# KM1M7CF05 register map
Vendor: Nuvoton Technology Corporation Japan; Series: KM1M7CF; File version: 1.0.3
CPU: CM7 r1p2, little endian, MPU, FPU, double-precision FPU, I-cache, D-cache, ITCM, DTCM, 4 interrupt priority bits
Registers are 16-bit, access per field, no defined reset value unless marked. A register's access mark holds for its fields unless they carry their own. Offsets are from the block's base; [hi:lo] are bit positions; {n}, {i} and the like mark numbered series.

## FL — Flash Memory
Base 0x4001C000
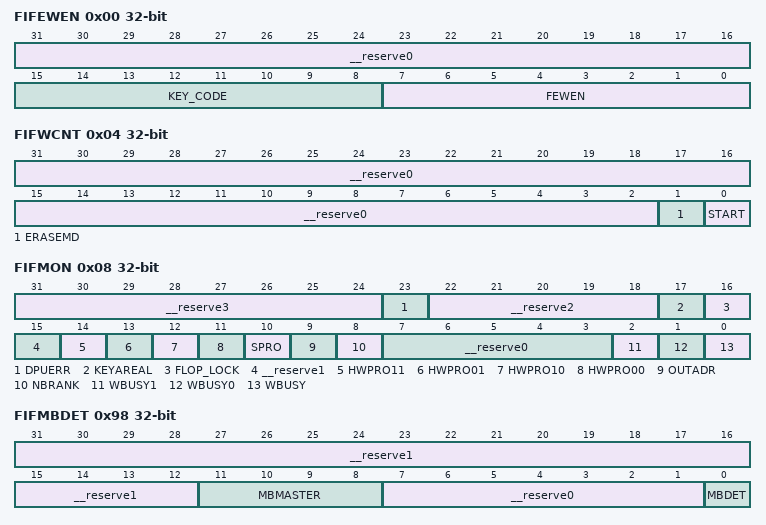
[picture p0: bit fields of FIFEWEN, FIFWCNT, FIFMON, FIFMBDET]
0x00 FIFEWEN 32-bit — Rewriting Enable Register
  [31:16] __reserve0 ro — "0" is always read out.
  [15:8] KEY_CODE wo — Register Key
  [7:0] FEWEN rw — Enable/disable the flash memory rewriting
0x04 FIFWCNT 32-bit — Rewriting Start Register
  [31:2] __reserve0 ro — "0" is always read out.
  [1] ERASEMD rw — Select Program/Erase function
  [0] START rw — Start Program/Erase function
0x08 FIFMON 32-bit ro — Rewriting Status Register
  [31:24] __reserve3 — "0" is always read out.
  [23] DPUERR — Rewrite error
  [22:18] __reserve2 — "0" is always read out.
  [17] KEYAREAL — KEYAREA area write protection error
  [16] FLOP_LOCK — Flash option area write protection error
  [15] __reserve1 — "0" is always read out.
  [14] HWPRO11 — Flash Bank1 HW protect 1 error flag
  [13] HWPRO01 — Flash Bank1 HW protect 0 error flag
  [12] HWPRO10 — Flash Bank0 HW protect 1 error flag
  [11] HWPRO00 — Flash Bank0 HW protect 0 error flag
  [10] SPRO — Rewriting SW protect error flag
  [9] OUTADR — Rewriting address error flag
  [8] NBRANK — Writing blank error flag
  [7:3] __reserve0 — "0" is always read out.
  [2] WBUSY1 — Flash Bank1 rewriting execution flag
  [1] WBUSY0 — Flash Bank0 rewriting execution flag
  [0] WBUSY — Rewriting execution flag
0x0C FIPEADR 32-bit rw — Rewriting Destination Address Register
  [31:0] PEADR — Rewriting (write/erase) address
{0x10+4i} FIWDATA{i} 32-bit rw (i=0..3) — Writing Data Register {i}
  [31:0] WDATA{i} — Set the data to be written to the flash memory. The data of [{32i+31}: {32i}] out of 128 bits will be rewritten.
0x20 FISPROSTR 32-bit rw — SW Protect Start Address
  [31:0] SPROSTR — SW protect start address
0x24 FISPROEND 32-bit rw — SW Protect End Address
  [31:0] SPROEND — SW protect end address
0x30 FIHPRO0STR0 32-bit ro — Flash Bank0 HW Protect 0 Start Address
  [31:0] HPRO0STR0 — Flash Bank0 HW protect 0 start address
0x34 FIHPRO0END0 32-bit ro — Flash Bank0 HW Protect 0 End Address
  [31:0] HPRO0END0 — Flash Bank0 HW protect 0 end address
0x38 FIHPRO1STR0 32-bit ro — Flash Bank0 HW Protect 1 Start Address
  [31:0] HPRO1STR0 — Flash Bank0 HW protect 1 start address
0x3C FIHPRO1END0 32-bit ro — Flash Bank0 HW Protect 1 End Address
  [31:0] HPRO1END0 — Flash Bank0 HW protect 1 end address
0x40 FIHPRO0STR1 32-bit ro — Flash Bank1 HW Protect 0 Start Address
  [31:0] HPRO0STR1 — Flash Bank1 HW protect 0 start address
0x44 FIHPRO0END1 32-bit ro — Flash Bank1 HW Protect 0 End Address
  [31:0] HPRO0END1 — Flash Bank1 HW protect 0 end address
0x48 FIHPRO1STR1 32-bit ro — Flash Bank1 HW Protect 1 Start Address
  [31:0] HPRO1STR1 — Flash Bank1 HW protect 1 start address
0x4C FIHPRO1END1 32-bit ro — Flash Bank1 HW Protect 1 End Address
  [31:0] HPRO1END1 — Flash Bank1 HW protect 1 end address
0x94 FIFMBEA 32-bit ro — Flash 2-bit or more Error Address
  [31:0] MBEA — Flash ECC 2-bit error interrupt target address
0x98 FIFMBDET 32-bit ro — Flash 2-bit or more Error Detection Register
  [31:12] __reserve1 — "0" is always read out.
  [11:8] MBMASTER — Flash ECC 2-bit error interrupt generation master information
  [7:1] __reserve0 — "0" is always read out.
  [0] MBDET — Flash ECC 2-bit error interrupt target address
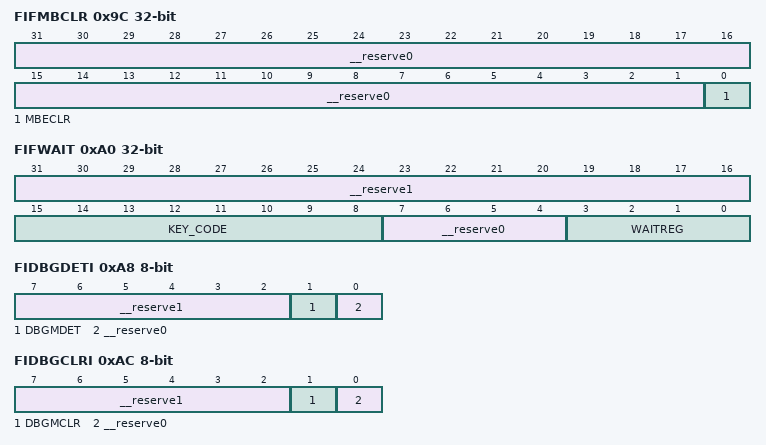
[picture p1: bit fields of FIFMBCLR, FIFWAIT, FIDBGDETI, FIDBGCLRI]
0x9C FIFMBCLR 32-bit — Flash 2-bit or more Error Interrupt Clear Register
  [31:1] __reserve0 ro — "0" is always read out.
  [0] MBECLR rw — [Write]
0xA0 FIFWAIT 32-bit — Flash Access Wait Control Register
  [31:16] __reserve1 ro — "0" is always read out.
  [15:8] KEY_CODE rw — Register Key
  [7:4] __reserve0 ro — "0" is always read out.
  [3:0] WAITREG rw — Flash Read access wait setting
0xA8 FIDBGDETI 8-bit ro — Flash Debug Access Error Detection Register
  [7:2] __reserve1 — "0" is always read out.
  [1] DBGMDET — Flash 2-bit or more error detection at debugger access
  [0] __reserve0 — "0" or "1" data is read out.
0xAC FIDBGCLRI 8-bit — Flash Debug Access Error Detection Clear Register
  [7:2] __reserve1 ro — "0" is always read out.
  [1] DBGMCLR rw — Flash 2-bit or more error detection at debugger access clear
  [0] __reserve0 ro — "0" is always read out.
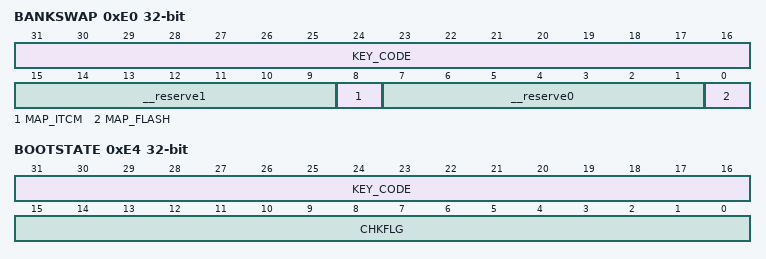
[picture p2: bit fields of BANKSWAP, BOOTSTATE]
0xE0 BANKSWAP 32-bit — Bank setting register
  [31:16] KEY_CODE rw — Register Key
  [15:9] __reserve1 ro — "0" is always read out.
  [8] MAP_ITCM rw — ITCM dual bank switching setting.
  [7:1] __reserve0 ro — "0" is always read out.
  [0] MAP_FLASH rw — Flash dual bank switching setting.
0xE4 BOOTSTATE 32-bit rw — Bank status register
  [31:16] KEY_CODE — Register Key
  [15:0] CHKFLG — The written value can be read.
